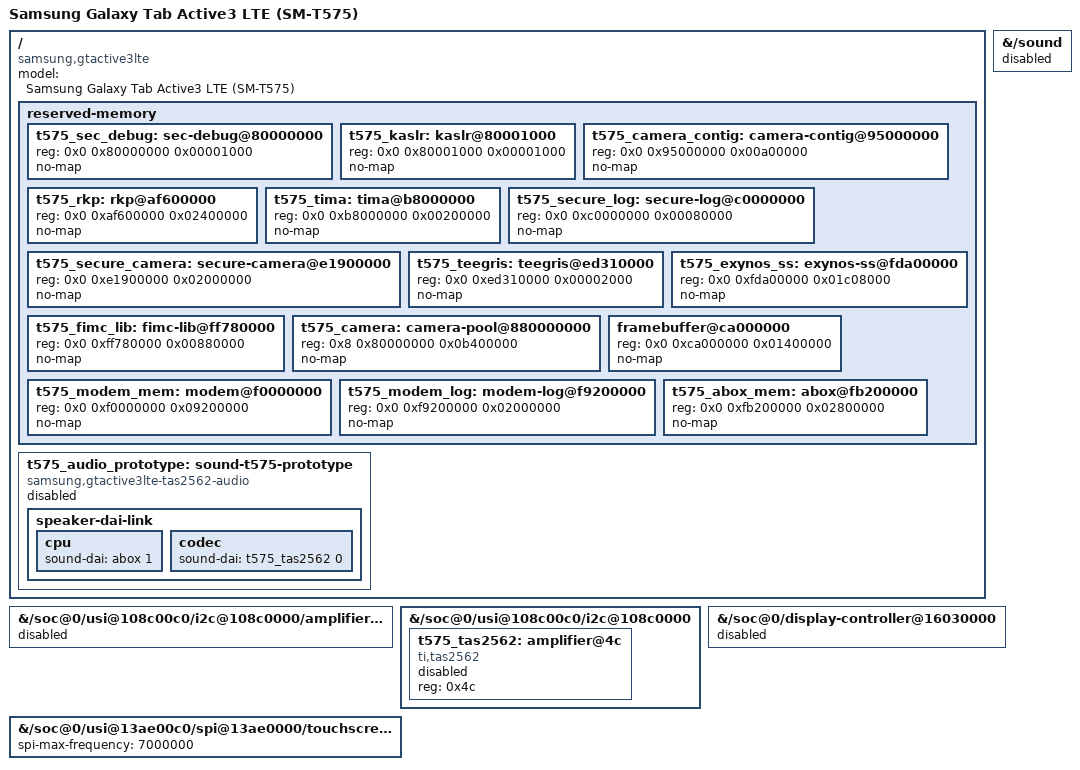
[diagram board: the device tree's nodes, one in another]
// SPDX-License-Identifier: GPL-2.0 OR BSD-3-Clause
/*
 * Samsung Galaxy Tab Active3 LTE SM-T575: first-stage compile-only DT.
 *
 * This inherits the exact SM-T570 Linux DT from the packaged postmarketOS
 * kernel patch. Different upstream development revisions may not expose
 * the same labels. Only board identification is overridden here.
 *
 * Not a validated hardware description or flashable image. Specifically,
 * the inherited hardware configuration has NOT been verified on the LTE
 * variant; do not use this DTB to boot the tablet.
 */
#include "exynos9810-gtactive3wifi.dts"

/ {
	model = "Samsung Galaxy Tab Active3 LTE (SM-T575)";
	compatible = "samsung,gtactive3lte", "samsung,exynos9810";

	/* Exclude LTE modem / coprocessor RAM even while their drivers are off. */
	reserved-memory {
		#address-cells = <2>;
		#size-cells = <1>;
		ranges;


		/*
		 * Additional fixed carveouts from the live SM-T575 Android FDT.
		 * Preserve all of these during *diagnostic* bring-up, even though
		 * the corresponding Samsung proprietary drivers aren't enabled.
		 * The dynamic ION video_stream and crypto pools have no fixed
		 * physical addresses and must be audited separately.
		 */
		t575_sec_debug: sec-debug@80000000 {
			reg = <0x0 0x80000000 0x00001000>;
			no-map;
		};

		t575_kaslr: kaslr@80001000 {
			reg = <0x0 0x80001000 0x00001000>;
			no-map;
		};

		t575_camera_contig: camera-contig@95000000 {
			reg = <0x0 0x95000000 0x00a00000>;
			no-map;
		};

		t575_rkp: rkp@af600000 {
			reg = <0x0 0xaf600000 0x02400000>;
			no-map;
		};

		t575_tima: tima@b8000000 {
			reg = <0x0 0xb8000000 0x00200000>;
			no-map;
		};

		t575_secure_log: secure-log@c0000000 {
			reg = <0x0 0xc0000000 0x00080000>;
			no-map;
		};

		t575_secure_camera: secure-camera@e1900000 {
			reg = <0x0 0xe1900000 0x02000000>;
			no-map;
		};

		t575_teegris: teegris@ed310000 {
			reg = <0x0 0xed310000 0x00002000>;
			no-map;
		};

		t575_exynos_ss: exynos-ss@fda00000 {
			reg = <0x0 0xfda00000 0x01c08000>;
			no-map;
		};

		t575_fimc_lib: fimc-lib@ff780000 {
			reg = <0x0 0xff780000 0x00880000>;
			no-map;
		};

		t575_camera: camera-pool@880000000 {
			reg = <0x8 0x80000000 0x0b400000>;
			no-map;
		};

		/*
		 * Samsung stock FDT reserves the entire 20 MiB S-Boot handover
		 * framebuffer, not just the 1200x1920x4 visible pixel bytes.
		 * Extend the inherited T570 reservation to avoid allocations
		 * into the unused tail while the bootloader may own it.
		 */
		framebuffer@ca000000 {
			reg = <0x0 0xca000000 0x01400000>;
			no-map;
		};

		t575_modem_mem: modem@f0000000 {
			reg = <0x0 0xf0000000 0x09200000>;
			no-map;
		};

		t575_modem_log: modem-log@f9200000 {
			reg = <0x0 0xf9200000 0x02000000>;
			no-map;
		};

		/* Vendor A-Box firmware region: DT node name differs from reg. */
		t575_abox_mem: abox@fb200000 {
			reg = <0x0 0xfb200000 0x02800000>;
			no-map;
		};
	};
};

/*
 * SM-T575 stock overlay 5 selects TI TAS2562 at 0x4c and explicitly
 * disables the Richtek RT5510 at 0x34. The inherited SM-T570 audio
 * machine and amplifier topology therefore cannot be used unchanged.
 *
 * Keep the wrong amp and board sound card disabled in this compile-only
 * prototype. Do NOT enable TAS2562 until its controller mapping, supplies,
 * reset/IRQ polarity, codec driver and ASoC DAI topology are validated.
 * No physical probe or boot test has been performed.
 */
&{/soc@0/usi@108c00c0/i2c@108c0000/amplifier@34} {
	status = "disabled";
};

/*
 * LTE-specific TAS2562 speaker amplifier, verified from Android DTBO #5:
 *  - same HSI2C controller as disabled T570 RT5510
 *  - 7-bit address 0x4c, compatible "ti,tas2562"
 *  - sound-dai = <&tas2562 0> referenced by vendor /sound/uaif@1/codec
 *  - #sound-dai-cells = <1>
 *
 * Deliberately DISABLED: Linux driver binding, audio supplies, shutdown
 * and reset handling, pinctrl, ABOX UAIF1 clocks and machine-card routing
 * have not been validated together. DO NOT make okay or enable sound yet.
 */
&{/soc@0/usi@108c00c0/i2c@108c0000} {
	t575_tas2562: amplifier@4c {
		compatible = "ti,tas2562";
		reg = <0x4c>;
		#sound-dai-cells = <1>;
		status = "disabled";
	};
};

&{/sound} {
	status = "disabled";
};

/*
 * Stage 45 speaker-only ASoC MACHINE PROTOTYPE. This is not the active
 * /sound device from T570; it is a new, distinct disabled root node.
 * The T575 vendor tree confirms UAIF1 -> TAS2562 DAI 0. I2S clock,
 * amplifier supplies and speaker DAPM routing remain to be verified.
 */
/ {
	t575_audio_prototype: sound-t575-prototype {
		compatible = "samsung,gtactive3lte-tas2562-audio";
		status = "disabled";

		speaker-dai-link {
			cpu {
				sound-dai = <&abox 1>;
			};
			codec {
				sound-dai = <&t575_tas2562 0>;
			};
		};
	};
};


/*
 * The T575 stock DTBO overlay 5 limits the Himax touchscreen on SPI21
 * to 7 MHz; the inherited T570 DTS described 10 MHz. Match the measured
 * vendor board configuration without changing GPIOs, firmware or power.
 */
&{/soc@0/usi@13ae00c0/spi@13ae0000/touchscreen@0} {
	spi-max-frequency = <7000000>;
};

/*
 * Stage 10 isolation: T570 DECON takeover KMS assumes S-Boot left window 5
 * scanning through IDMA_G0, and accepts any nonzero IDMA base address. This
 * has NOT been measured on the SM-T575. Do not let the driver seize aperture
 * ownership or flip a DMA register before verifying LTE scanout state.
 *
 * The bootloader framebuffer description stays intact, for a separate
 * simple-framebuffer / simpledrm compatibility investigation.
 * This DTS is still not approved for boot or flashing.
 */
&{/soc@0/display-controller@16030000} {
	status = "disabled";
};
